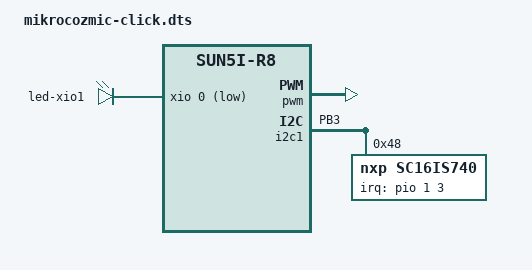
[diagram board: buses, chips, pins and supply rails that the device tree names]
/*
 * Copyright 2017 cozmIC
 *
 * Pierre-Jean TEXIER <pjtexier@cozmic.co>
 *
 * This file is dual-licensed: you can use it either under the terms
 * of the GPL or the X11 license, at your option. Note that this dual
 * licensing only applies to this file, and not this project as a
 * whole.
 *
 *  a) This file is free software; you can redistribute it and/or
 *     modify it under the terms of the GNU General Public License as
 *     published by the Free Software Foundation; either version 2 of the
 *     License, or (at your option) any later version.
 *
 *     This file is distributed in the hope that it will be useful,
 *     but WITHOUT ANY WARRANTY; without even the implied warranty of
 *     MERCHANTABILITY or FITNESS FOR A PARTICULAR PURPOSE.  See the
 *     GNU General Public License for more details.
 *
 * Or, alternatively,
 *
 *  b) Permission is hereby granted, free of charge, to any person
 *     obtaining a copy of this software and associated documentation
 *     files (the "Software"), to deal in the Software without
 *     restriction, including without limitation the rights to use,
 *     copy, modify, merge, publish, distribute, sublicense, and/or
 *     sell copies of the Software, and to permit persons to whom the
 *     Software is furnished to do so, subject to the following
 *     conditions:
 *
 *     The above copyright notice and this permission notice shall be
 *     included in all copies or substantial portions of the Software.
 *
 *     THE SOFTWARE IS PROVIDED "AS IS", WITHOUT WARRANTY OF ANY KIND,
 *     EXPRESS OR IMPLIED, INCLUDING BUT NOT LIMITED TO THE WARRANTIES
 *     OF MERCHANTABILITY, FITNESS FOR A PARTICULAR PURPOSE AND
 *     NONINFRINGEMENT. IN NO EVENT SHALL THE AUTHORS OR COPYRIGHT
 *     HOLDERS BE LIABLE FOR ANY CLAIM, DAMAGES OR OTHER LIABILITY,
 *     WHETHER IN AN ACTION OF CONTRACT, TORT OR OTHERWISE, ARISING
 *     FROM, OUT OF OR IN CONNECTION WITH THE SOFTWARE OR THE USE OR
 *     OTHER DEALINGS IN THE SOFTWARE.
 */

/dts-v1/;
/plugin/;

#include <dt-bindings/gpio/gpio.h>
#include <dt-bindings/pinctrl/sun4i-a10.h>
#include <dt-bindings/interrupt-controller/irq.h>

/ {
	compatible = "nextthing,chip", "allwinner,sun5i-r8";
	
	/* Enable the PWM */
	fragment@0 {
	
		target = <&pwm>;
		
		__overlay__ {
		
			pinctrl-names = "default";
			pinctrl-0 = <&pwm0_pins>;
			status = "okay";
		};
	};
		
	/* Enable i2c to UART */
	fragment@1 {
	
		target = <&i2c1>;

		__overlay__ {
		
			#address-cells = <1>;
                        #size-cells = <0>;
			pinctrl-names = "default";
			pinctrl-0 = <&chip_en>;
			status = "okay";
			
			sc16is740: sc16is740@48 {
				compatible = "nxp,sc16is740";
			    	reg = <0x48>;
			    	clocks = <&osc14M>;
			    	interrupt-parent = <&pio>;
				interrupts = <1 3 IRQ_TYPE_EDGE_FALLING>;						
         		};
                };
	};
	
	fragment@2 {
	
		target = <&pio>;

		__overlay__ {
		
			chip_en: chip_en@0 {
				allwinner,pins = "PB3";
				allwinner,function = "gpio_in";
				allwinner,drive = <SUN4I_PINCTRL_10_MA>;
				allwinner,pull = <SUN4I_PINCTRL_NO_PULL>;           	
			};
		};
	};
	
	/* Enable GPIO LED */
	fragment@3 {
	
		target-path = "/";

		__overlay__ {
		
			gpio-leds {
			
				compatible = "gpio-leds";

				led-xio1 {
					gpios = <&xio 0 1>;
					linux,default-trigger = "heartbeat";
				};
			};
		};
	};
};

